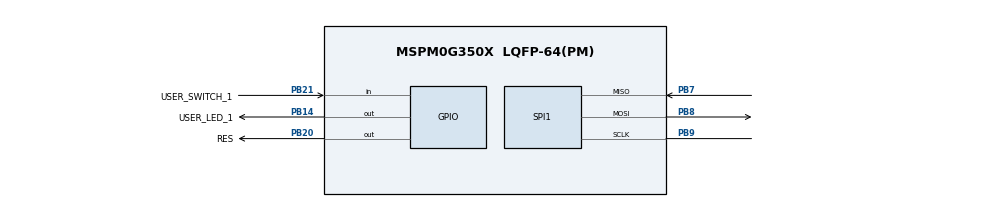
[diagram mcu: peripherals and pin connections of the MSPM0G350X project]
/**
 *
 * @cliArgs --device "MSPM0G350X" --part "Default" --package "LQFP-64(PM)" --product "mspm0_sdk@2.11.00.07"
 * @versions {"tool":"1.28.0+4696"}
 */

/**
 * Import the modules used in this configuration.
 */
const ADC12   = scripting.addModule("/ti/driverlib/ADC12", {}, false);
const ADC121  = ADC12.addInstance();
const DAC12   = scripting.addModule("/ti/driverlib/DAC12");
const GPIO    = scripting.addModule("/ti/driverlib/GPIO", {}, false);
const GPIO1   = GPIO.addInstance();
const GPIO2   = GPIO.addInstance();
const GPIO3   = GPIO.addInstance();
const SPI     = scripting.addModule("/ti/driverlib/SPI", {}, false);
const SPI1    = SPI.addInstance();
const SYSCTL  = scripting.addModule("/ti/driverlib/SYSCTL");
const SYSTICK = scripting.addModule("/ti/driverlib/SYSTICK");
const TIMER   = scripting.addModule("/ti/driverlib/TIMER", {}, false);
const TIMER1  = TIMER.addInstance();
const TIMER2  = TIMER.addInstance();
const TIMER3  = TIMER.addInstance();

/**
 * Write custom configuration values to the imported modules.
 */
const gate8  = system.clockTree["MFPCLKGATE"];
gate8.enable = true;

ADC121.$name                             = "ADC12_0";
ADC121.adcMem1chansel                    = "DL_ADC12_INPUT_CHAN_1";
ADC121.adcMem3chansel                    = "DL_ADC12_INPUT_CHAN_3";
ADC121.sampClkSrc                        = "DL_ADC12_CLOCK_ULPCLK";
ADC121.repeatMode                        = true;
ADC121.sampleTime0                       = "62.5ns";
ADC121.sampleMode                        = "DL_ADC12_SAMPLING_SOURCE_MANUAL";
ADC121.trigSrc                           = "DL_ADC12_TRIG_SRC_EVENT";
ADC121.enableFIFO                        = true;
ADC121.powerDownMode                     = "DL_ADC12_POWER_DOWN_MODE_MANUAL";
ADC121.configureDMA                      = true;
ADC121.enabledDMATriggers                = ["DL_ADC12_DMA_MEM10_RESULT_LOADED"];
ADC121.subChanID                         = 1;
ADC121.enabledInterrupts                 = ["DL_ADC12_INTERRUPT_DMA_DONE"];
ADC121.sampCnt                           = 6;
ADC121.adcMem2chansel                    = "DL_ADC12_INPUT_CHAN_2";
ADC121.adcPin0Config.$name               = "ti_driverlib_gpio_GPIOPinGeneric0";
ADC121.DMA_CHANNEL.$name                 = "DMA_CH0";
ADC121.DMA_CHANNEL.addressMode           = "f2b";
ADC121.DMA_CHANNEL.configureTransferSize = true;
ADC121.DMA_CHANNEL.transferSize          = 2048;
ADC121.DMA_CHANNEL.transferMode          = "FULL_CH_REPEAT_SINGLE";

const Board = scripting.addModule("/ti/driverlib/Board", {}, false);

DAC12.dacFIFOEn                = true;
DAC12.dacConfigureDMA          = true;
DAC12.dacFIFOThresh            = "TWO_QTRS_EMPTY";
DAC12.dacSampleTimerRate       = "1M";
DAC12.dacOutputPinEn           = true;
DAC12.sub0ChanID               = 2;
DAC12.dacFIFOTrigger           = "HWTRIG0";
DAC12.dacSampleTimerEn         = false;
DAC12.DMA_CHANNEL.$name        = "DMA_CH1";
DAC12.DMA_CHANNEL.addressMode  = "b2f";
DAC12.DMA_CHANNEL.srcLength    = "HALF_WORD";
DAC12.DMA_CHANNEL.dstLength    = "HALF_WORD";
DAC12.DMA_CHANNEL.transferMode = "FULL_CH_REPEAT_SINGLE";
DAC12.OutPinConfig.$name       = "ti_driverlib_gpio_GPIOPinGeneric1";

GPIO1.$name                              = "GPIO_SWITCHES";
GPIO1.associatedPins[0].$name            = "USER_SWITCH_1";
GPIO1.associatedPins[0].direction        = "INPUT";
GPIO1.associatedPins[0].internalResistor = "PULL_UP";
GPIO1.associatedPins[0].pin.$assign      = "PB21";

GPIO2.$name                          = "GPIO_LEDS";
GPIO2.associatedPins[0].$name        = "USER_LED_1";
GPIO2.associatedPins[0].initialValue = "SET";
GPIO2.associatedPins[0].pin.$assign  = "PB14";

GPIO3.$name                          = "LCD";
GPIO3.associatedPins.create(4);
GPIO3.associatedPins[0].$name        = "RES";
GPIO3.associatedPins[0].assignedPort = "PORTB";
GPIO3.associatedPins[0].assignedPin  = "20";
GPIO3.associatedPins[0].pin.$assign  = "PB20";
GPIO3.associatedPins[1].$name        = "DC";
GPIO3.associatedPins[1].assignedPort = "PORTB";
GPIO3.associatedPins[1].assignedPin  = "22";
GPIO3.associatedPins[2].$name        = "CS";
GPIO3.associatedPins[2].initialValue = "SET";
GPIO3.associatedPins[2].assignedPort = "PORTB";
GPIO3.associatedPins[2].assignedPin  = "23";
GPIO3.associatedPins[3].$name        = "BLK";
GPIO3.associatedPins[3].initialValue = "SET";
GPIO3.associatedPins[3].assignedPort = "PORTB";
GPIO3.associatedPins[3].assignedPin  = "24";

SPI1.$name                              = "SPI_LCD";
SPI1.frameFormat                        = "MOTO3";
SPI1.sclkPinConfig.direction            = scripting.forceWrite("OUTPUT");
SPI1.sclkPinConfig.onlyInternalResistor = scripting.forceWrite(false);
SPI1.sclkPinConfig.passedPeripheralType = scripting.forceWrite("Digital");
SPI1.sclkPinConfig.$name                = "ti_driverlib_gpio_GPIOPinGeneric2";
SPI1.mosiPinConfig.direction            = scripting.forceWrite("OUTPUT");
SPI1.mosiPinConfig.hideOutputInversion  = scripting.forceWrite(false);
SPI1.mosiPinConfig.onlyInternalResistor = scripting.forceWrite(false);
SPI1.mosiPinConfig.passedPeripheralType = scripting.forceWrite("Digital");
SPI1.mosiPinConfig.$name                = "ti_driverlib_gpio_GPIOPinGeneric3";
SPI1.misoPinConfig.onlyInternalResistor = scripting.forceWrite(false);
SPI1.misoPinConfig.passedPeripheralType = scripting.forceWrite("Digital");
SPI1.misoPinConfig.$name                = "ti_driverlib_gpio_GPIOPinGeneric4";
SPI1.peripheral.$assign                 = "SPI1";
SPI1.peripheral.sclkPin.$assign         = "PB9";
SPI1.peripheral.mosiPin.$assign         = "PB8";
SPI1.peripheral.misoPin.$assign         = "PB7";

SYSCTL.forceDefaultClkConfig = true;
SYSCTL.MFPCLKEn              = true;

SYSTICK.period        = 32000;
SYSTICK.periodEnable  = true;
SYSTICK.systickEnable = true;

TIMER1.$name                       = "TIMER_0";
TIMER1.timerPeriod                 = "1us";
TIMER1.timerStartTimer             = true;
TIMER1.timerMode                   = "PERIODIC";
TIMER1.event1PublisherChannel      = 1;
TIMER1.event1ControllerInterruptEn = ["ZERO_EVENT"];

TIMER2.$name                       = "TIMER_1";
TIMER2.timerPeriod                 = "15.625us";
TIMER2.timerStartTimer             = true;
TIMER2.event1PublisherChannel      = 2;
TIMER2.event1ControllerInterruptEn = ["ZERO_EVENT"];
TIMER2.timerMode                   = "PERIODIC";

TIMER3.$name            = "TIMER_KEY";
TIMER3.timerPeriod      = "20 ms";
TIMER3.timerMode        = "PERIODIC";
TIMER3.timerClkDiv      = 8;
TIMER3.timerClkPrescale = 8;
TIMER3.timerStartTimer  = true;
TIMER3.interrupts       = ["ZERO"];

/**
 * Pinmux solution for unlocked pins/peripherals. This ensures that minor changes to the automatic solver in a future
 * version of the tool will not impact the pinmux you originally saw.  These lines can be completely deleted in order to
 * re-solve from scratch.
 */
ADC121.peripheral.$suggestSolution             = "ADC0";
ADC121.peripheral.adcPin0.$suggestSolution     = "PA27";
ADC121.DMA_CHANNEL.peripheral.$suggestSolution = "DMA_CH1";
Board.peripheral.$suggestSolution              = "DEBUGSS";
Board.peripheral.swclkPin.$suggestSolution     = "PA20";
Board.peripheral.swdioPin.$suggestSolution     = "PA19";
DAC12.DMA_CHANNEL.peripheral.$suggestSolution  = "DMA_CH0";
DAC12.peripheral.$suggestSolution              = "DAC0";
DAC12.peripheral.OutPin.$suggestSolution       = "PA15";
GPIO3.associatedPins[1].pin.$suggestSolution   = "PB22";
GPIO3.associatedPins[2].pin.$suggestSolution   = "PB23";
GPIO3.associatedPins[3].pin.$suggestSolution   = "PB24";
SYSCTL.peripheral.$suggestSolution             = "SYSCTL";
TIMER1.peripheral.$suggestSolution             = "TIMG0";
TIMER2.peripheral.$suggestSolution             = "TIMA1";
TIMER3.peripheral.$suggestSolution             = "TIMA0";
